# FE310 register map
Vendor: SiFive
Registers are 32-bit, read-write, reset 0x0 unless marked. A register's access mark holds for its fields unless they carry their own. Offsets are from the block's base; lines under a group give offsets from that group; [hi:lo] are bit positions; {n}, {i} and the like mark numbered series; 'fields as' and 'values as' point back to an identical list; <NAME> marks a mode.

## Memory map
0x02000000 CLINT — Coreplex Local Interrupts
0x0C000000 PLIC — Platform Level Interrupt Control
0x10000000 AON — Always On
0x10008000 PRCI — Power Reset Clock Interrupts
0x10010000 OTP — One Time Programmable Memory
0x10012000 GPIO0 — General Purpose Input Output
0x10013000 UART0 — Universal Asynchronous Receiver Transmitter
0x10014000 QSPI0 — Quad Serial Peripheral Interface
0x10015000 PWM0 — 8-bit timer with 4 cmp
0x10023000 UART1
0x10024000 QSPI1
0x10025000 PWM1
0x10034000 QSPI2
0x10035000 PWM2

## Interrupts
1 WATCHDOG (AON)
2 RTC (AON)
3 UART0
4 UART1
5 QSPI0
6 QSPI1
7 QSPI2
8 GPIO0
{n+8} GPIO{n} (GPIO0) (n=1..31)
40 PWM0CMP0 (PWM0)
41 PWM0CMP1 (PWM0)
42 PWM0CMP2 (PWM0)
43 PWM0CMP3 (PWM0)
44 PWM1Cmp0 (PWM1)
45 PWM1CMP1 (PWM1)
46 PWM1CMP2 (PWM1)
47 PWM1CMP3 (PWM1)
48 PWM2CMP0 (PWM2)
49 PWM2CMP1 (PWM2)
50 PWM2CMP2 (PWM2)
51 PWM2CMP3 (PWM2)

## CLINT — Coreplex Local Interrupts
Base 0x02000000
0x00 msip — Hart 0 software interrupt register
  [0] value
0x4000 mtimecmplo — Hart 0 time comparator register
0x4004 mtimecmphi — Hart 0 time comparator register
0xBFF8 mtimelo — Timer register
0xBFFC mtimehi — Timer register

## PLIC — Platform Level Interrupt Control
Base 0x0C000000
0x04 priority1 — Interrupt Priority Register
0x1000 pending0to31 — Interrupt Pending Register
0x2000 enable0to31 — Interrupt Enable Register
0x200000 threshold — Priority Threshold Register
0x200004 claim — Claim/Complete Register

## AON — Always On
Base 0x10000000
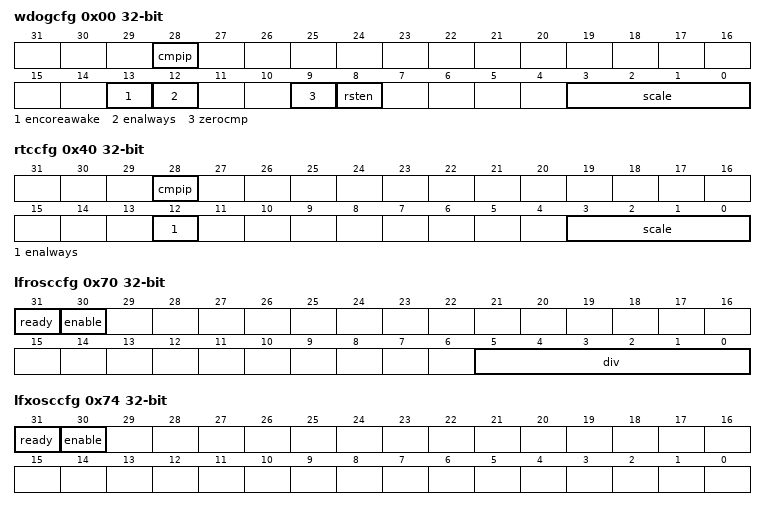
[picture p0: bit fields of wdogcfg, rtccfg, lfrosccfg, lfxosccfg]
0x00 wdogcfg — Watchdog Configuration Register
  [28] cmpip, [13] encoreawake, [12] enalways, [9] zerocmp, [8] rsten, [3:0] scale
0x08 wdogcount — Watchdog Counter Register
0x10 wdogs — Watchdog Scaled Counter Register
0x18 wdogfeed — Watchdog Feed Register
0x1C wdogkey wo reset 0x51F15E — Watchdog Key Register
0x20 wdogcmp — Watchdog Compare Register
  [15:0] value
0x40 rtccfg — RTC Configuration Register
  [28] cmpip, [12] enalways, [3:0] scale
0x48 rtclo — RTC Counter Low Register
0x4C rtchi — RTC Counter High Register
  [15:0] value
0x50 rtcs — RTC Scaled Counter Register
0x60 rtccmp — RTC Compare Register
0x70 lfrosccfg — AON Clock Configuration Register
  [31] ready, [30] enable, [5:0] div
0x74 lfxosccfg — AON Clock Configuration Register
  [31] ready, [30] enable
{0x80+4i} backup{i} (i=0..31) — Backup Register
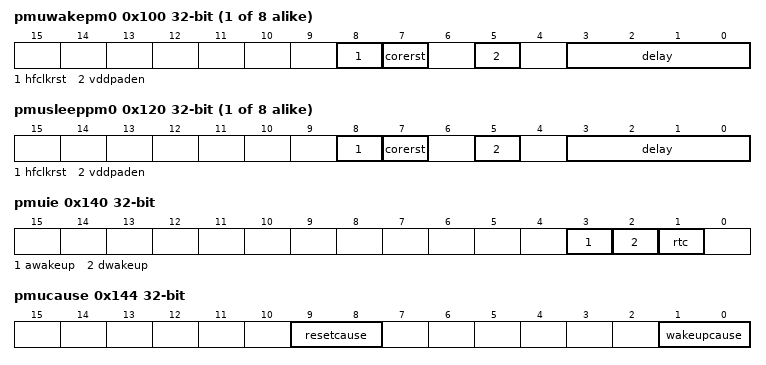
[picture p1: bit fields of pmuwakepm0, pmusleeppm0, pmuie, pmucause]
{0x100+4i} pmuwakepm{i} (i=0..7) — PMU Wake Program Memory
  [8] hfclkrst, [7] corerst, [5] vddpaden, [3:0] delay
{0x120+4i} pmusleeppm{i} (i=0..7) — PMU Sleep Program Memory
  [8] hfclkrst, [7] corerst, [5] vddpaden, [3:0] delay
0x140 pmuie — PMU Interrupt Enable Register
  [3] awakeup, [2] dwakeup, [1] rtc
0x144 pmucause
  [9:8] resetcause
    0=Power-on reset; 1=External reset; 2=Watchdog reset
  [1:0] wakeupcause
    0=Power-on wakeup; 1=External wakeup; 2=Watchdog wakeup
0x148 pmusleep wo
  [0] sleep
0x14C pmukey wo reset 0x51F15E

## PRCI — Power Reset Clock Interrupts
Base 0x10008000
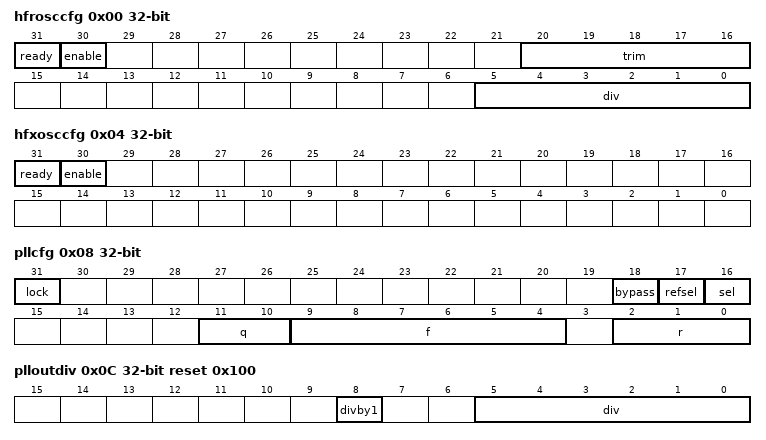
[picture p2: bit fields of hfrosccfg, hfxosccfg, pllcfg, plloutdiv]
0x00 hfrosccfg — Clock Configuration Register
  [31] ready, [30] enable, [20:16] trim, [5:0] div
0x04 hfxosccfg — Clock Configuration Register
  [31] ready, [30] enable
0x08 pllcfg — PLL Configuration Register
  [31] lock, [18] bypass, [17] refsel, [16] sel, [11:10] q, [9:4] f, [2:0] r
0x0C plloutdiv reset 0x100 — PLL Divider Register
  [8] divby1, [5:0] div
0x10 coreclkcfg — Clock Configuration Register

## GPIO0 — General Purpose Input Output
Base 0x10012000
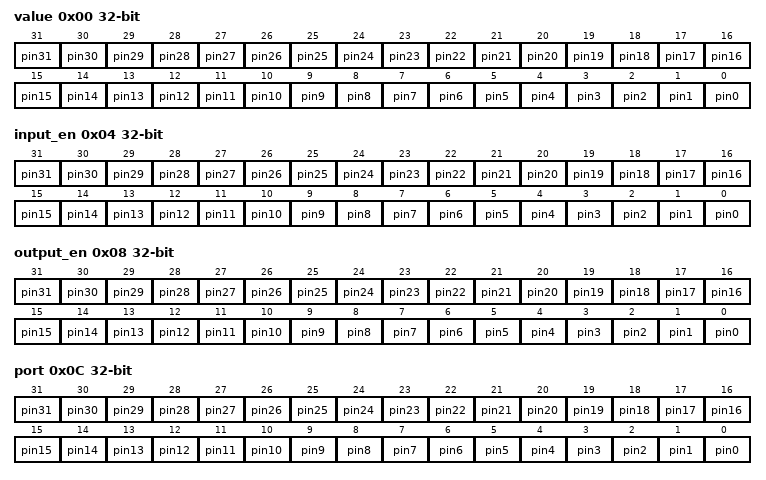
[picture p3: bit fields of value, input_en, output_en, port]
0x00 value — Pin value.
  [n] pin{n} (n=0..31)
0x04 input_en — Pin Input Enable Register
  [n] pin{n} (n=0..31)
0x08 output_en — Pin Output Enable Register
  [n] pin{n} (n=0..31)
0x0C port — Output Port Value Register
  [n] pin{n} (n=0..31)
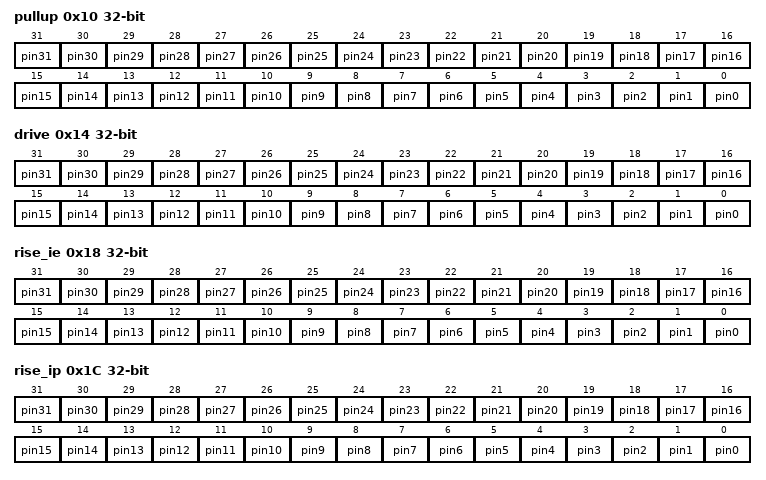
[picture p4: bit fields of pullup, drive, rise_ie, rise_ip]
0x10 pullup — Internal Pull-Up Enable Register
  [n] pin{n} (n=0..31)
0x14 drive — Drive Strength Register
  [n] pin{n} (n=0..31)
0x18 rise_ie — Rise Interrupt Enable Register
  [n] pin{n} (n=0..31)
0x1C rise_ip — Rise Interrupt Pending Register
  [n] pin{n} (n=0..31)
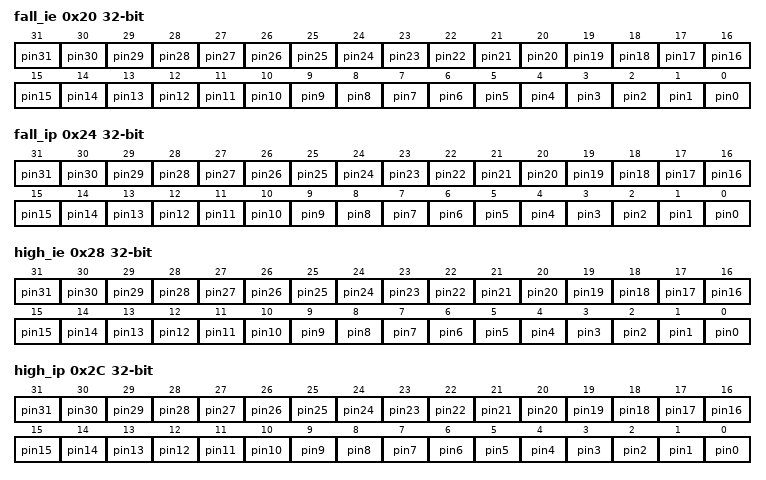
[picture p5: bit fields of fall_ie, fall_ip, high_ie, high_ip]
0x20 fall_ie — Fall Interrupt Enable Register
  [n] pin{n} (n=0..31)
0x24 fall_ip — Fall Interrupt Pending Register
  [n] pin{n} (n=0..31)
0x28 high_ie — High Interrupt Enable Register
  [n] pin{n} (n=0..31)
0x2C high_ip — High Interrupt Pending Register
  [n] pin{n} (n=0..31)
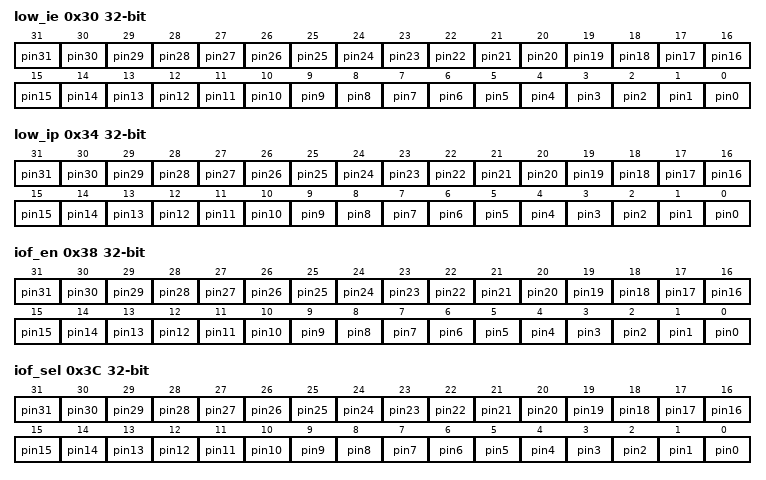
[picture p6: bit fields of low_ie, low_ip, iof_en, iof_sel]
0x30 low_ie — Low Interrupt Enable Register
  [n] pin{n} (n=0..31)
0x34 low_ip — Low Interrupt Pending Register
  [n] pin{n} (n=0..31)
0x38 iof_en — HW I/O Function Enable Register
  [n] pin{n} (n=0..31)
0x3C iof_sel — HW I/O Function Select Register
  [n] pin{n} (n=0..31)
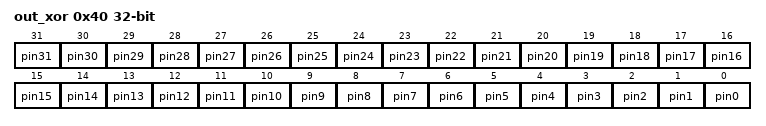
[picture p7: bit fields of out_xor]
0x40 out_xor — Output XOR (invert) Register
  [n] pin{n} (n=0..31)

## UART0 — Universal Asynchronous Receiver Transmitter
Base 0x10013000
Same registers: UART1 0x10023000
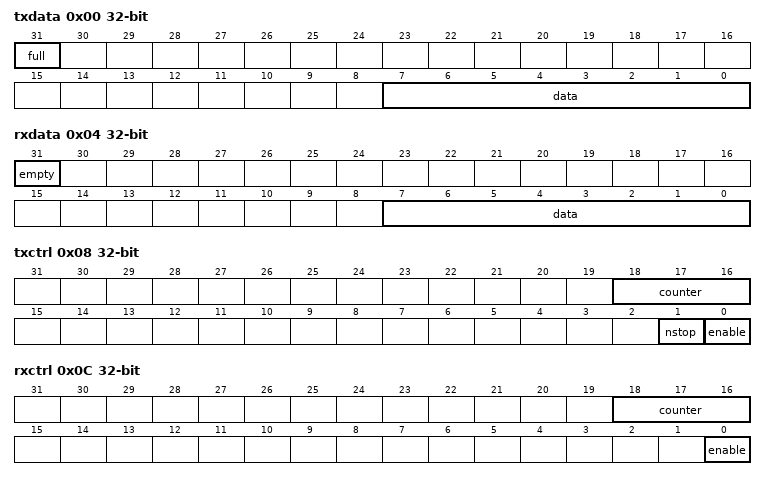
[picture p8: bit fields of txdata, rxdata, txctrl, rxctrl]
0x00 txdata — Transmit Data Register
  [31] full, [7:0] data
0x04 rxdata — Receive Data Register
  [31] empty, [7:0] data
0x08 txctrl — Transmit Control Register
  [18:16] counter, [1] nstop, [0] enable
0x0C rxctrl — Receive Control Register
  [18:16] counter, [0] enable
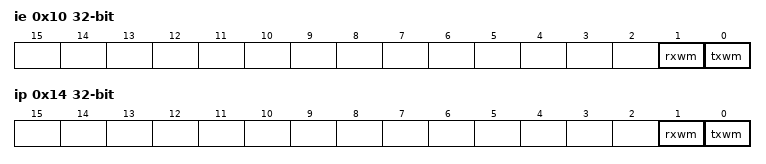
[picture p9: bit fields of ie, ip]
0x10 ie — Interrupt Enable Register
  [1] rxwm, [0] txwm
0x14 ip — Interrupt Pending Register
  [1] rxwm, [0] txwm
0x18 div — Baud Rate Divisor Register
  [15:0] value

## QSPI0 — Quad Serial Peripheral Interface
Base 0x10014000
Same registers: QSPI1 0x10024000, QSPI2 0x10034000
0x00 div — Serial Clock Divisor Register
  [11:0] value
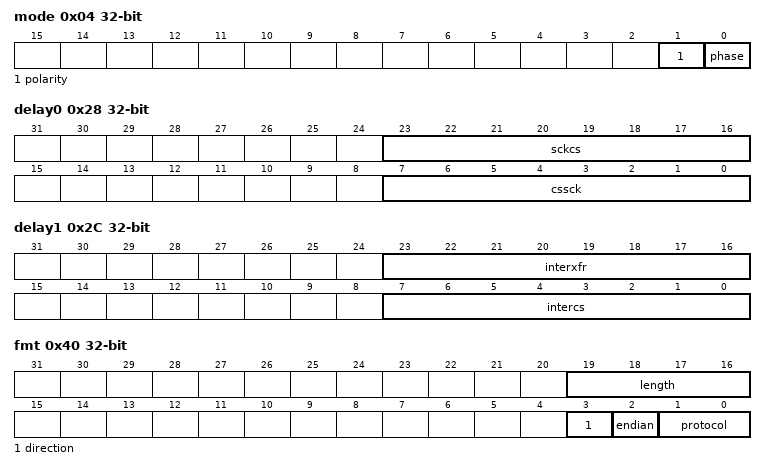
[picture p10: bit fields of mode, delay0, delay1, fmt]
0x04 mode — Serial Clock Mode Register
  [1] polarity, [0] phase
0x10 csid — Chip Select ID Register
0x14 csdef reset 0xFFFF — Chip Select Default Register
0x18 csmode — Chip Select Mode Register
0x28 delay0 — Delay Control 0 Register
  [23:16] sckcs, [7:0] cssck
0x2C delay1 — Delay Control 1 Register
  [23:16] interxfr, [7:0] intercs
0x40 fmt — Frame Format Register
  [19:16] length
  [3] direction
    0=Rx (For dual and quad protocols, the DQ pins are tri-stated. For the single protocol, the DQ0 pin is driven with the transmit data as normal.); 1=Tx (The receive FIFO is not populated.)
  [2] endian
  [1:0] protocol
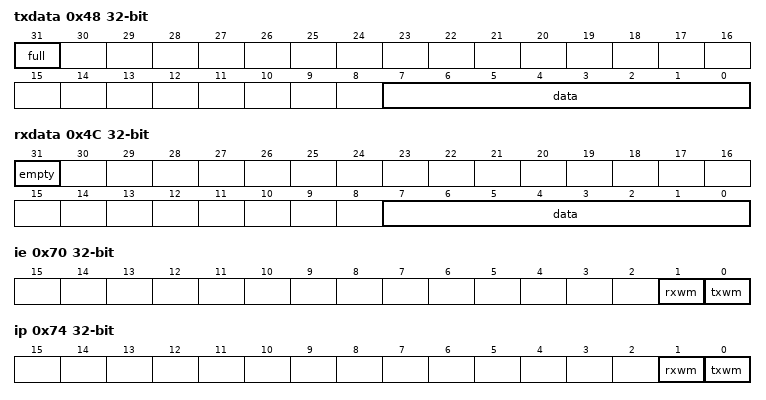
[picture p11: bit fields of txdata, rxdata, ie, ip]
0x48 txdata — Transmit Data Register
  [31] full, [7:0] data
0x4C rxdata — Receive Data Register
  [31] empty, [7:0] data
0x50 txmark — Transmit Watermark Register
  [2:0] value
0x54 rxmark — Receive Watermark Register
  [2:0] value
0x60 fctrl — SPI Flash Interface Control Register
  [0] enable
0x64 ffmt — SPI Flash Instruction Format Register
  [31:24] pad_code — First 8 bits to transmit during dummy cycles
  [23:16] cmd_code — Value of command byte
  [13:12] data_proto — Protocol for receiving data bytes
  [11:10] addr_proto — Protocol for transmitting address and padding
  [9:8] cmd_proto — Protocol for transmitting command
  [3:1] addr_len — Number of address bytes (0 to 4)
  [0] pad_cnt — Number of dummy cycles
  [0] cmd_en — Enable sending of command
0x70 ie — SPI Interrupt Enable Register
  [1] rxwm, [0] txwm
0x74 ip — SPI Interrupt Pending Register
  [1] rxwm, [0] txwm

## PWM0 — 8-bit timer with 4 cmp
Base 0x10015000
Same registers: PWM1 0x10025000, PWM2 0x10035000
0x00 cfg — PWM Configuration Register
  [n+28] cmp{n}ip (n=0..3)
  [27] cmp3gang
  [36:26] cmp2gang
  [25] cmp1gang
  [24] cmp0gang
  [n+16] cmp{n}center (n=0..3)
  [13:12] enable
    2=OneShot (Increments counter until overflow.); 1=Always (Increments counter.); 0=Off (Doesn't increment counter.)
  [10] deglitch
  [9] zerocmp
  [8] sticky
  [3:0] scale
0x04 count — Counter Register
0x10 pwms — Scaled Halfword Counter Register
{0x20+4i} cmp{i} (i=0..3) — Compare Register
  [15:0] value
